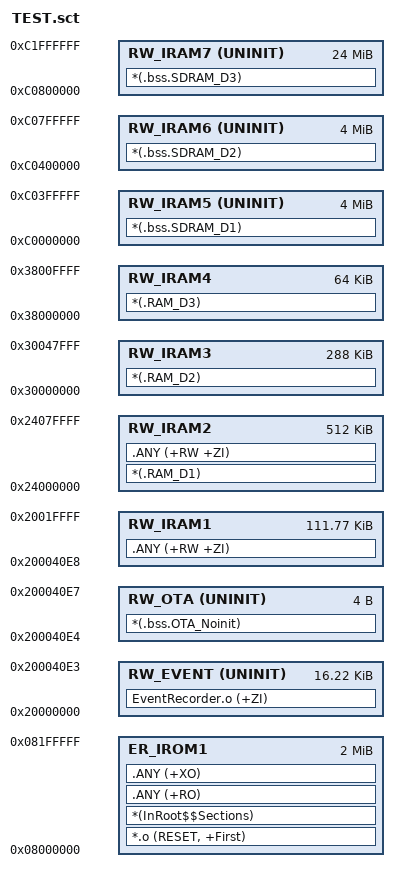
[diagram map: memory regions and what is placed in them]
; *************************************************************
; *** Scatter-Loading Description File generated by uVision ***
; *************************************************************

LR_IROM1 0x08000000 0x00200000  {    ; load region size_region
  ER_IROM1 0x08000000 0x00200000  {  ; load address = execution address
   *.o (RESET, +First)
   *(InRoot$$Sections)
   .ANY (+RO)
   .ANY (+XO)
  }
  
  RW_EVENT 0x20000000 UNINIT 0x000040E4  {  ; RW data - 16KB DTCM eventrecorder选择1024*16byte 会比这个值稍大一点
	 EventRecorder.o (+ZI)
  }
  
  RW_OTA 0x200040E4 UNINIT 0x00000004  {  ; RW data - 4byte DTCM
   *(.bss.OTA_Noinit)
  }
  
   RW_IRAM1 0x200040E8 0x0001BF18  {  ; RW data - 128KB - 16KB - 4byte DTCM
   .ANY (+RW +ZI)
  }
  
  RW_IRAM2 0x24000000 0x00080000  {  ; RW data - 512KB AXI SRAM
   *(.RAM_D1)
   .ANY (+RW +ZI)
  }
  
  RW_IRAM3 0x30000000 0x00048000  {  ; RW data - 128KB SRAM1(0x30000000) + 128KB SRAM2(0x3002 0000) + 32KB SRAM3(0x30040000)
   *(.RAM_D2)
  }
  
  RW_IRAM4 0x38000000 0x00010000  {  ; RW data - 64KB SRAM4(0x38000000)
   *(.RAM_D3)
  }
  
  RW_IRAM5 0xC0000000 UNINIT 0x00400000  {  ; RW data - 4MB SDRAM(0xC0000000)
   *(.bss.SDRAM_D1)
  }
  RW_IRAM6 0xC0400000 UNINIT 0x00400000  {  ; RW data - 4MB SDRAM(0xC0400000)
   *(.bss.SDRAM_D2)
  }
  RW_IRAM7 0xC0800000 UNINIT 0x01800000  {  ; RW data - 24MB SDRAM(0xC0400000)
   *(.bss.SDRAM_D3)
  }
}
